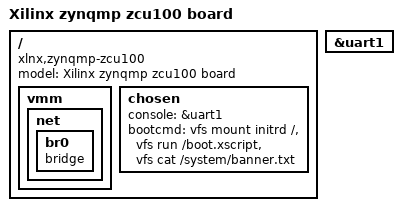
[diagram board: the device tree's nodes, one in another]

/dts-v1/;

#include "./zynqmp.dtsi"

/ {
	model = "Xilinx zynqmp zcu100 board";
	compatible = "xlnx,zynqmp-zcu100";

	vmm {
		net {
			br0 {
				device_type = "netswitch";
				compatible = "bridge";
			};
		};
	};

	chosen {
		console = &uart1;
		bootcmd = /* Mount initrd device */
			  "vfs mount initrd /",

			  /* Run boot script */
			  "vfs run /boot.xscript",

			  /* Print banner */
			  "vfs cat /system/banner.txt";
	};
};

&uart1 {
	status = "okay";
};
